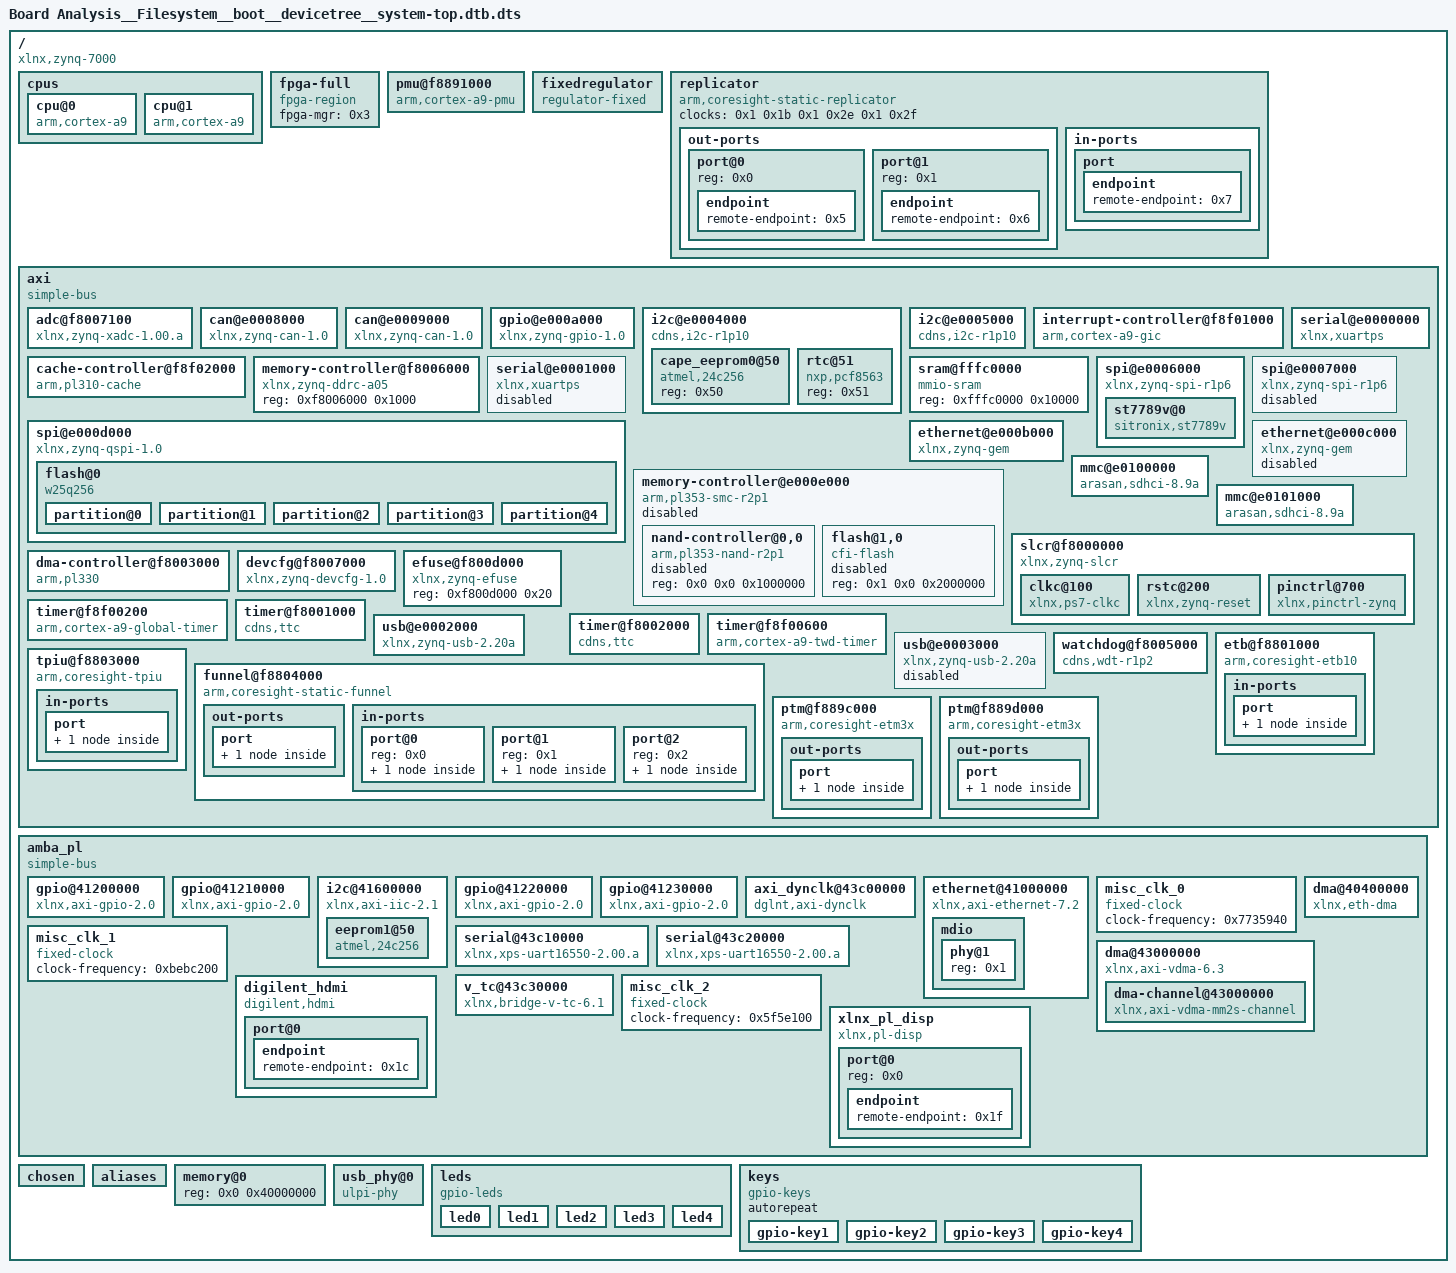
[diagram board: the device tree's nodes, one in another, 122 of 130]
/dts-v1/;
/ {
	#address-cells = <0x1>;
	#size-cells = <0x1>;
	compatible = "xlnx,zynq-7000";
	cpus {
		#address-cells = <0x1>;
		#size-cells = <0x0>;
		cpu@0 {
			compatible = "arm,cortex-a9";
			device_type = "cpu";
			reg = <0x0>;
			clocks = <0x1 0x3>;
			clock-latency = <0x3e8>;
			cpu0-supply = <0x2>;
			operating-points = <0xbb2ca 0xf4240 0x5d965 0xf4240>;
			phandle = <0x10>;
		};
		cpu@1 {
			compatible = "arm,cortex-a9";
			device_type = "cpu";
			reg = <0x1>;
			clocks = <0x1 0x3>;
			phandle = <0x12>;
		};
	};
	fpga-full {
		compatible = "fpga-region";
		fpga-mgr = <0x3>;
		#address-cells = <0x1>;
		#size-cells = <0x1>;
		ranges;
		phandle = <0x20>;
	};
	pmu@f8891000 {
		compatible = "arm,cortex-a9-pmu";
		interrupts = <0x0 0x5 0x4 0x0 0x6 0x4>;
		interrupt-parent = <0x4>;
		reg = <0xf8891000 0x1000 0xf8893000 0x1000>;
	};
	fixedregulator {
		compatible = "regulator-fixed";
		regulator-name = "VCCPINT";
		regulator-min-microvolt = <0xf4240>;
		regulator-max-microvolt = <0xf4240>;
		regulator-boot-on;
		regulator-always-on;
		phandle = <0x2>;
	};
	replicator {
		compatible = "arm,coresight-static-replicator";
		clocks = <0x1 0x1b 0x1 0x2e 0x1 0x2f>;
		clock-names = "apb_pclk", "dbg_trc", "dbg_apb";
		out-ports {
			#address-cells = <0x1>;
			#size-cells = <0x0>;
			port@0 {
				reg = <0x0>;
				endpoint {
					remote-endpoint = <0x5>;
					phandle = <0xc>;
				};
			};
			port@1 {
				reg = <0x1>;
				endpoint {
					remote-endpoint = <0x6>;
					phandle = <0xb>;
				};
			};
		};
		in-ports {
			port {
				endpoint {
					remote-endpoint = <0x7>;
					phandle = <0xd>;
				};
			};
		};
	};
	axi {
		u-boot,dm-pre-reloc;
		compatible = "simple-bus";
		#address-cells = <0x1>;
		#size-cells = <0x1>;
		interrupt-parent = <0x4>;
		ranges;
		phandle = <0x21>;
		adc@f8007100 {
			compatible = "xlnx,zynq-xadc-1.00.a";
			reg = <0xf8007100 0x20>;
			interrupts = <0x0 0x7 0x4>;
			interrupt-parent = <0x4>;
			clocks = <0x1 0xc>;
			phandle = <0x22>;
		};
		can@e0008000 {
			compatible = "xlnx,zynq-can-1.0";
			status = "okay";
			clocks = <0x1 0x13 0x1 0x24>;
			clock-names = "can_clk", "pclk";
			reg = <0xe0008000 0x1000>;
			interrupts = <0x0 0x1c 0x4>;
			interrupt-parent = <0x4>;
			tx-fifo-depth = <0x40>;
			rx-fifo-depth = <0x40>;
			phandle = <0x23>;
		};
		can@e0009000 {
			compatible = "xlnx,zynq-can-1.0";
			status = "okay";
			clocks = <0x1 0x14 0x1 0x25>;
			clock-names = "can_clk", "pclk";
			reg = <0xe0009000 0x1000>;
			interrupts = <0x0 0x33 0x4>;
			interrupt-parent = <0x4>;
			tx-fifo-depth = <0x40>;
			rx-fifo-depth = <0x40>;
			phandle = <0x24>;
		};
		gpio@e000a000 {
			compatible = "xlnx,zynq-gpio-1.0";
			#gpio-cells = <0x2>;
			clocks = <0x1 0x2a>;
			gpio-controller;
			interrupt-controller;
			#interrupt-cells = <0x2>;
			interrupt-parent = <0x4>;
			interrupts = <0x0 0x14 0x4>;
			reg = <0xe000a000 0x1000>;
			emio-gpio-width = <0xb>;
			gpio-mask-high = <0x0>;
			gpio-mask-low = <0x5600>;
			phandle = <0x8>;
		};
		i2c@e0004000 {
			compatible = "cdns,i2c-r1p10";
			status = "okay";
			clocks = <0x1 0x26>;
			interrupt-parent = <0x4>;
			interrupts = <0x0 0x19 0x4>;
			reg = <0xe0004000 0x1000>;
			#address-cells = <0x1>;
			#size-cells = <0x0>;
			clock-frequency = <0x186a0>;
			phandle = <0x25>;
			cape_eeprom0@50 {
				compatible = "atmel,24c256";
				reg = <0x50>;
				phandle = <0x26>;
			};
			rtc@51 {
				compatible = "nxp,pcf8563";
				reg = <0x51>;
			};
		};
		i2c@e0005000 {
			compatible = "cdns,i2c-r1p10";
			status = "okay";
			clocks = <0x1 0x27>;
			interrupt-parent = <0x4>;
			interrupts = <0x0 0x30 0x4>;
			reg = <0xe0005000 0x1000>;
			#address-cells = <0x1>;
			#size-cells = <0x0>;
			clock-frequency = <0x186a0>;
			phandle = <0x1b>;
		};
		interrupt-controller@f8f01000 {
			compatible = "arm,cortex-a9-gic";
			#interrupt-cells = <0x3>;
			interrupt-controller;
			reg = <0xf8f01000 0x1000 0xf8f00100 0x100>;
			num_cpus = <0x2>;
			num_interrupts = <0x60>;
			phandle = <0x4>;
		};
		cache-controller@f8f02000 {
			compatible = "arm,pl310-cache";
			reg = <0xf8f02000 0x1000>;
			interrupts = <0x0 0x2 0x4>;
			arm,data-latency = <0x3 0x2 0x2>;
			arm,tag-latency = <0x2 0x2 0x2>;
			cache-unified;
			cache-level = <0x2>;
			phandle = <0x27>;
		};
		memory-controller@f8006000 {
			compatible = "xlnx,zynq-ddrc-a05";
			reg = <0xf8006000 0x1000>;
			phandle = <0x28>;
		};
		sram@fffc0000 {
			compatible = "mmio-sram";
			reg = <0xfffc0000 0x10000>;
			phandle = <0x29>;
		};
		serial@e0000000 {
			compatible = "xlnx,xuartps", "cdns,uart-r1p8";
			status = "okay";
			clocks = <0x1 0x17 0x1 0x28>;
			clock-names = "uart_clk", "pclk";
			reg = <0xe0000000 0x1000>;
			interrupts = <0x0 0x1b 0x4>;
			cts-override;
			device_type = "serial";
			port-number = <0x0>;
			phandle = <0x2a>;
		};
		serial@e0001000 {
			compatible = "xlnx,xuartps", "cdns,uart-r1p8";
			status = "disabled";
			clocks = <0x1 0x18 0x1 0x29>;
			clock-names = "uart_clk", "pclk";
			reg = <0xe0001000 0x1000>;
			interrupts = <0x0 0x32 0x4>;
			phandle = <0x2b>;
		};
		spi@e0006000 {
			compatible = "xlnx,zynq-spi-r1p6";
			reg = <0xe0006000 0x1000>;
			status = "okay";
			interrupt-parent = <0x4>;
			interrupts = <0x0 0x1a 0x4>;
			clocks = <0x1 0x19 0x1 0x22>;
			clock-names = "ref_clk", "pclk";
			#address-cells = <0x1>;
			#size-cells = <0x0>;
			is-decoded-cs = <0x0>;
			num-cs = <0x3>;
			phandle = <0x2c>;
			st7789v@0 {
				status = "okay";
				compatible = "sitronix,st7789v";
				reg = <0x0>;
				spi-max-frequency = <0x1e84800>;
				rotate = <0x10e>;
				spi-cpol;
				spi-cpha;
				rgb;
				fps = <0x1e>;
				buswidth = <0x8>;
				reset-gpios = <0x8 0x3d 0x1>;
				dc-gpios = <0x8 0x3b 0x0>;
				width = <0xac>;
				height = <0x140>;
				debug = <0x0>;
			};
		};
		spi@e0007000 {
			compatible = "xlnx,zynq-spi-r1p6";
			reg = <0xe0007000 0x1000>;
			status = "disabled";
			interrupt-parent = <0x4>;
			interrupts = <0x0 0x31 0x4>;
			clocks = <0x1 0x1a 0x1 0x23>;
			clock-names = "ref_clk", "pclk";
			#address-cells = <0x1>;
			#size-cells = <0x0>;
			phandle = <0x2d>;
		};
		spi@e000d000 {
			compatible = "xlnx,zynq-qspi-1.0";
			reg = <0xe000d000 0x1000>;
			interrupt-parent = <0x4>;
			interrupts = <0x0 0x13 0x4>;
			clocks = <0x1 0xa 0x1 0x2b>;
			clock-names = "ref_clk", "pclk";
			status = "okay";
			#address-cells = <0x1>;
			#size-cells = <0x0>;
			is-dual = <0x0>;
			num-cs = <0x1>;
			spi-rx-bus-width = <0x4>;
			spi-tx-bus-width = <0x4>;
			phandle = <0x2e>;
			flash@0 {
				compatible = "w25q256", "jedec,spi-nor";
				reg = <0x0>;
				spi-max-frequency = <0x2faf080>;
				#address-cells = <0x1>;
				#size-cells = <0x1>;
				phandle = <0x2f>;
				partition@0 {
					label = "boot";
					reg = <0x0 0x800000>;
				};
				partition@1 {
					label = "bootenv";
					reg = <0x800000 0x20000>;
				};
				partition@2 {
					label = "kernel";
					reg = <0x820000 0xa80000>;
				};
				partition@3 {
					label = "boot.scr";
					reg = <0x12a0000 0x40000>;
				};
				partition@4 {
					label = "space";
					reg = <0x12e0000 0x0>;
				};
			};
		};
		ethernet@e000b000 {
			compatible = "xlnx,zynq-gem", "cdns,gem";
			reg = <0xe000b000 0x1000>;
			status = "okay";
			interrupts = <0x0 0x16 0x4>;
			clocks = <0x1 0x1e 0x1 0x1e 0x1 0xd>;
			clock-names = "pclk", "hclk", "tx_clk";
			#address-cells = <0x1>;
			#size-cells = <0x0>;
			phy-mode = "rgmii-id";
			xlnx,ptp-enet-clock = <0x79dbbf3>;
			local-mac-address = [00 0a 35 00 1e 53];
			phandle = <0x30>;
		};
		ethernet@e000c000 {
			compatible = "xlnx,zynq-gem", "cdns,gem";
			reg = <0xe000c000 0x1000>;
			status = "disabled";
			interrupts = <0x0 0x2d 0x4>;
			clocks = <0x1 0x1f 0x1 0x1f 0x1 0xe>;
			clock-names = "pclk", "hclk", "tx_clk";
			#address-cells = <0x1>;
			#size-cells = <0x0>;
			phandle = <0x31>;
		};
		memory-controller@e000e000 {
			compatible = "arm,pl353-smc-r2p1", "arm,primecell";
			reg = <0xe000e000 0x1000>;
			status = "disabled";
			clock-names = "memclk", "apb_pclk";
			clocks = <0x1 0xb 0x1 0x2c>;
			ranges = <0x0 0x0 0xe1000000 0x1000000 0x1 0x0 0xe2000000 0x2000000 0x2 0x0 0xe4000000 0x2000000>;
			#address-cells = <0x2>;
			#size-cells = <0x1>;
			interrupt-parent = <0x4>;
			interrupts = <0x0 0x12 0x4>;
			phandle = <0x32>;
			nand-controller@0,0 {
				compatible = "arm,pl353-nand-r2p1";
				reg = <0x0 0x0 0x1000000>;
				status = "disabled";
				#address-cells = <0x1>;
				#size-cells = <0x0>;
				phandle = <0x33>;
			};
			flash@1,0 {
				status = "disabled";
				compatible = "cfi-flash";
				reg = <0x1 0x0 0x2000000>;
				#address-cells = <0x1>;
				#size-cells = <0x1>;
				phandle = <0x34>;
			};
		};
		mmc@e0100000 {
			compatible = "arasan,sdhci-8.9a";
			status = "okay";
			clock-names = "clk_xin", "clk_ahb";
			clocks = <0x1 0x15 0x1 0x20>;
			interrupt-parent = <0x4>;
			interrupts = <0x0 0x18 0x4>;
			reg = <0xe0100000 0x1000>;
			xlnx,has-cd = <0x1>;
			xlnx,has-power = <0x0>;
			xlnx,has-wp = <0x0>;
			u-boot,dm-pre-reloc;
			phandle = <0x35>;
		};
		mmc@e0101000 {
			compatible = "arasan,sdhci-8.9a";
			status = "okay";
			clock-names = "clk_xin", "clk_ahb";
			clocks = <0x1 0x16 0x1 0x21>;
			interrupt-parent = <0x4>;
			interrupts = <0x0 0x2f 0x4>;
			reg = <0xe0101000 0x1000>;
			xlnx,has-cd = <0x0>;
			xlnx,has-power = <0x0>;
			xlnx,has-wp = <0x0>;
			phandle = <0x36>;
		};
		slcr@f8000000 {
			u-boot,dm-pre-reloc;
			#address-cells = <0x1>;
			#size-cells = <0x1>;
			compatible = "xlnx,zynq-slcr", "syscon", "simple-mfd";
			reg = <0xf8000000 0x1000>;
			ranges;
			phandle = <0x9>;
			clkc@100 {
				u-boot,dm-pre-reloc;
				#clock-cells = <0x1>;
				compatible = "xlnx,ps7-clkc";
				fclk-enable = <0x3>;
				clock-output-names = "armpll", "ddrpll", "iopll", "cpu_6or4x", "cpu_3or2x", "cpu_2x", "cpu_1x", "ddr2x", "ddr3x", "dci", "lqspi", "smc", "pcap", "gem0", "gem1", "fclk0", "fclk1", "fclk2", "fclk3", "can0", "can1", "sdio0", "sdio1", "uart0", "uart1", "spi0", "spi1", "dma", "usb0_aper", "usb1_aper", "gem0_aper", "gem1_aper", "sdio0_aper", "sdio1_aper", "spi0_aper", "spi1_aper", "can0_aper", "can1_aper", "i2c0_aper", "i2c1_aper", "uart0_aper", "uart1_aper", "gpio_aper", "lqspi_aper", "smc_aper", "swdt", "dbg_trc", "dbg_apb";
				reg = <0x100 0x100>;
				ps-clk-frequency = <0x1fca055>;
				phandle = <0x1>;
			};
			rstc@200 {
				compatible = "xlnx,zynq-reset";
				reg = <0x200 0x48>;
				#reset-cells = <0x1>;
				syscon = <0x9>;
				phandle = <0x37>;
			};
			pinctrl@700 {
				compatible = "xlnx,pinctrl-zynq";
				reg = <0x700 0x200>;
				syscon = <0x9>;
				phandle = <0x38>;
			};
		};
		dma-controller@f8003000 {
			compatible = "arm,pl330", "arm,primecell";
			reg = <0xf8003000 0x1000>;
			interrupt-parent = <0x4>;
			interrupts = <0x0 0xd 0x4 0x0 0xe 0x4 0x0 0xf 0x4 0x0 0x10 0x4 0x0 0x11 0x4 0x0 0x28 0x4 0x0 0x29 0x4 0x0 0x2a 0x4 0x0 0x2b 0x4>;
			#dma-cells = <0x1>;
			clocks = <0x1 0x1b>;
			clock-names = "apb_pclk";
			phandle = <0x39>;
		};
		devcfg@f8007000 {
			compatible = "xlnx,zynq-devcfg-1.0";
			reg = <0xf8007000 0x100>;
			interrupt-parent = <0x4>;
			interrupts = <0x0 0x8 0x4>;
			clocks = <0x1 0xc 0x1 0xf 0x1 0x10 0x1 0x11 0x1 0x12>;
			clock-names = "ref_clk", "fclk0", "fclk1", "fclk2", "fclk3";
			syscon = <0x9>;
			phandle = <0x3>;
		};
		efuse@f800d000 {
			compatible = "xlnx,zynq-efuse";
			reg = <0xf800d000 0x20>;
			phandle = <0x3a>;
		};
		timer@f8f00200 {
			compatible = "arm,cortex-a9-global-timer";
			reg = <0xf8f00200 0x20>;
			interrupts = <0x1 0xb 0x301>;
			interrupt-parent = <0x4>;
			clocks = <0x1 0x4>;
			phandle = <0x3b>;
		};
		timer@f8001000 {
			interrupt-parent = <0x4>;
			interrupts = <0x0 0xa 0x4 0x0 0xb 0x4 0x0 0xc 0x4>;
			compatible = "cdns,ttc";
			clocks = <0x1 0x6>;
			reg = <0xf8001000 0x1000>;
			phandle = <0x3c>;
		};
		timer@f8002000 {
			interrupt-parent = <0x4>;
			interrupts = <0x0 0x25 0x4 0x0 0x26 0x4 0x0 0x27 0x4>;
			compatible = "cdns,ttc";
			clocks = <0x1 0x6>;
			reg = <0xf8002000 0x1000>;
			phandle = <0x3d>;
		};
		timer@f8f00600 {
			interrupt-parent = <0x4>;
			interrupts = <0x1 0xd 0x301>;
			compatible = "arm,cortex-a9-twd-timer";
			reg = <0xf8f00600 0x20>;
			clocks = <0x1 0x4>;
			phandle = <0x3e>;
		};
		usb@e0002000 {
			compatible = "xlnx,zynq-usb-2.20a", "chipidea,usb2";
			status = "okay";
			clocks = <0x1 0x1c>;
			interrupt-parent = <0x4>;
			interrupts = <0x0 0x15 0x4>;
			reg = <0xe0002000 0x1000>;
			phy_type = "ulpi";
			usb-reset = <0x8 0xd 0x0>;
			dr_mode = "host";
			usb-phy = <0xa>;
			phandle = <0x3f>;
		};
		usb@e0003000 {
			compatible = "xlnx,zynq-usb-2.20a", "chipidea,usb2";
			status = "disabled";
			clocks = <0x1 0x1d>;
			interrupt-parent = <0x4>;
			interrupts = <0x0 0x2c 0x4>;
			reg = <0xe0003000 0x1000>;
			phy_type = "ulpi";
			phandle = <0x40>;
		};
		watchdog@f8005000 {
			clocks = <0x1 0x2d>;
			compatible = "cdns,wdt-r1p2";
			interrupt-parent = <0x4>;
			interrupts = <0x0 0x9 0x1>;
			reg = <0xf8005000 0x1000>;
			timeout-sec = <0xa>;
			phandle = <0x41>;
		};
		etb@f8801000 {
			compatible = "arm,coresight-etb10", "arm,primecell";
			reg = <0xf8801000 0x1000>;
			clocks = <0x1 0x1b 0x1 0x2e 0x1 0x2f>;
			clock-names = "apb_pclk", "dbg_trc", "dbg_apb";
			in-ports {
				port {
					endpoint {
						remote-endpoint = <0xb>;
						phandle = <0x6>;
					};
				};
			};
		};
		tpiu@f8803000 {
			compatible = "arm,coresight-tpiu", "arm,primecell";
			reg = <0xf8803000 0x1000>;
			clocks = <0x1 0x1b 0x1 0x2e 0x1 0x2f>;
			clock-names = "apb_pclk", "dbg_trc", "dbg_apb";
			in-ports {
				port {
					endpoint {
						remote-endpoint = <0xc>;
						phandle = <0x5>;
					};
				};
			};
		};
		funnel@f8804000 {
			compatible = "arm,coresight-static-funnel", "arm,primecell";
			reg = <0xf8804000 0x1000>;
			clocks = <0x1 0x1b 0x1 0x2e 0x1 0x2f>;
			clock-names = "apb_pclk", "dbg_trc", "dbg_apb";
			out-ports {
				port {
					endpoint {
						remote-endpoint = <0xd>;
						phandle = <0x7>;
					};
				};
			};
			in-ports {
				#address-cells = <0x1>;
				#size-cells = <0x0>;
				port@0 {
					reg = <0x0>;
					endpoint {
						remote-endpoint = <0xe>;
						phandle = <0x11>;
					};
				};
				port@1 {
					reg = <0x1>;
					endpoint {
						remote-endpoint = <0xf>;
						phandle = <0x13>;
					};
				};
				port@2 {
					reg = <0x2>;
					endpoint {
						phandle = <0x42>;
					};
				};
			};
		};
		ptm@f889c000 {
			compatible = "arm,coresight-etm3x", "arm,primecell";
			reg = <0xf889c000 0x1000>;
			clocks = <0x1 0x1b 0x1 0x2e 0x1 0x2f>;
			clock-names = "apb_pclk", "dbg_trc", "dbg_apb";
			cpu = <0x10>;
			out-ports {
				port {
					endpoint {
						remote-endpoint = <0x11>;
						phandle = <0xe>;
					};
				};
			};
		};
		ptm@f889d000 {
			compatible = "arm,coresight-etm3x", "arm,primecell";
			reg = <0xf889d000 0x1000>;
			clocks = <0x1 0x1b 0x1 0x2e 0x1 0x2f>;
			clock-names = "apb_pclk", "dbg_trc", "dbg_apb";
			cpu = <0x12>;
			out-ports {
				port {
					endpoint {
						remote-endpoint = <0x13>;
						phandle = <0xf>;
					};
				};
			};
		};
	};
	amba_pl {
		#address-cells = <0x1>;
		#size-cells = <0x1>;
		compatible = "simple-bus";
		ranges;
		phandle = <0x43>;
		gpio@41200000 {
			#gpio-cells = <0x2>;
			clock-names = "s_axi_aclk";
			clocks = <0x1 0xf>;
			compatible = "xlnx,axi-gpio-2.0", "xlnx,xps-gpio-1.00.a";
			gpio-controller;
			reg = <0x41200000 0x10000>;
			xlnx,all-inputs = <0x0>;
			xlnx,all-inputs-2 = <0x0>;
			xlnx,all-outputs = <0x0>;
			xlnx,all-outputs-2 = <0x0>;
			xlnx,dout-default = <0x0>;
			xlnx,dout-default-2 = <0x0>;
			xlnx,gpio-width = <0x20>;
			xlnx,gpio2-width = <0x20>;
			xlnx,interrupt-present = <0x0>;
			xlnx,is-dual = <0x1>;
			xlnx,tri-default = <0xffffffff>;
			xlnx,tri-default-2 = <0xffffffff>;
			phandle = <0x44>;
		};
		gpio@41210000 {
			#gpio-cells = <0x2>;
			clock-names = "s_axi_aclk";
			clocks = <0x1 0xf>;
			compatible = "xlnx,axi-gpio-2.0", "xlnx,xps-gpio-1.00.a";
			gpio-controller;
			reg = <0x41210000 0x10000>;
			xlnx,all-inputs = <0x0>;
			xlnx,all-inputs-2 = <0x0>;
			xlnx,all-outputs = <0x0>;
			xlnx,all-outputs-2 = <0x0>;
			xlnx,dout-default = <0x0>;
			xlnx,dout-default-2 = <0x0>;
			xlnx,gpio-width = <0x8>;
			xlnx,gpio2-width = <0x20>;
			xlnx,interrupt-present = <0x0>;
			xlnx,is-dual = <0x0>;
			xlnx,tri-default = <0xffffffff>;
			xlnx,tri-default-2 = <0xffffffff>;
			phandle = <0x45>;
		};
		i2c@41600000 {
			#address-cells = <0x1>;
			#size-cells = <0x0>;
			clock-names = "s_axi_aclk";
			clocks = <0x1 0xf>;
			compatible = "xlnx,axi-iic-2.1", "xlnx,xps-iic-2.00.a";
			interrupt-names = "iic2intc_irpt";
			interrupt-parent = <0x4>;
			interrupts = <0x0 0x34 0x4>;
			reg = <0x41600000 0x10000>;
			clock-frequency = <0x186a0>;
			phandle = <0x46>;
			eeprom1@50 {
				compatible = "atmel,24c256";
				reg = <0x50>;
				pagesize = <0x20>;
			};
		};
		gpio@41220000 {
			#gpio-cells = <0x2>;
			clock-names = "s_axi_aclk";
			clocks = <0x1 0xf>;
			compatible = "xlnx,axi-gpio-2.0", "xlnx,xps-gpio-1.00.a";
			gpio-controller;
			reg = <0x41220000 0x10000>;
			xlnx,all-inputs = <0x0>;
			xlnx,all-inputs-2 = <0x0>;
			xlnx,all-outputs = <0x0>;
			xlnx,all-outputs-2 = <0x0>;
			xlnx,dout-default = <0x0>;
			xlnx,dout-default-2 = <0x0>;
			xlnx,gpio-width = <0x20>;
			xlnx,gpio2-width = <0x2>;
			xlnx,interrupt-present = <0x0>;
			xlnx,is-dual = <0x1>;
			xlnx,tri-default = <0xffffffff>;
			xlnx,tri-default-2 = <0xffffffff>;
			phandle = <0x47>;
		};
		gpio@41230000 {
			#gpio-cells = <0x2>;
			clock-names = "s_axi_aclk";
			clocks = <0x1 0xf>;
			compatible = "xlnx,axi-gpio-2.0", "xlnx,xps-gpio-1.00.a";
			gpio-controller;
			reg = <0x41230000 0x10000>;
			xlnx,all-inputs = <0x0>;
			xlnx,all-inputs-2 = <0x0>;
			xlnx,all-outputs = <0x0>;
			xlnx,all-outputs-2 = <0x0>;
			xlnx,dout-default = <0x0>;
			xlnx,dout-default-2 = <0x0>;
			xlnx,gpio-width = <0x2>;
			xlnx,gpio2-width = <0x20>;
			xlnx,interrupt-present = <0x0>;
			xlnx,is-dual = <0x0>;
			xlnx,tri-default = <0xffffffff>;
			xlnx,tri-default-2 = <0xffffffff>;
			phandle = <0x48>;
		};
		axi_dynclk@43c00000 {
			clock-names = "REF_CLK_I", "s_axi_lite_aclk";
			clocks = <0x1 0xf>;
			compatible = "dglnt,axi-dynclk";
			reg = <0x43c00000 0x10000>;
			#clock-cells = <0x0>;
			phandle = <0x1a>;
		};
		ethernet@41000000 {
			axistream-connected = <0x14>;
			axistream-control-connected = <0x14>;
			clock-frequency = <0x5f5e100>;
			clock-names = "s_axi_lite_clk", "axis_clk", "gtx_clk", "ref_clk";
			clocks = <0x1 0xf 0x1 0xf 0x15 0x16>;
			compatible = "xlnx,axi-ethernet-7.2", "xlnx,axi-ethernet-1.00.a";
			device_type = "network";
			interrupt-names = "mac_irq", "interrupt", "mm2s_introut", "s2mm_introut";
			interrupt-parent = <0x4>;
			interrupts = <0x0 0x1d 0x1 0x0 0x1e 0x4 0x0 0x1f 0x4 0x0 0x20 0x4>;
			local-mac-address = [00 0a 35 00 01 22];
			phy-mode = "rgmii-rxid";
			reg = <0x41000000 0x40000>;
			xlnx = <0x0>;
			xlnx,axiliteclkrate = <0x0>;
			xlnx,axisclkrate = <0x0>;
			xlnx,channel-ids = "1";
			xlnx,clockselection = <0x0>;
			xlnx,enableasyncsgmii = <0x0>;
			xlnx,gt-type = <0x0>;
			xlnx,gtinex = <0x0>;
			xlnx,gtlocation = <0x0>;
			xlnx,gtrefclksrc = <0x0>;
			xlnx,include-dre;
			xlnx,instantiatebitslice0 = <0x0>;
			xlnx,num-queues = [00 01];
			xlnx,phyaddr = <0x1>;
			xlnx,phyrst-board-interface-dummy-port = <0x0>;
			xlnx,rable = <0x0>;
			xlnx,rxcsum = <0x2>;
			xlnx,rxlane0-placement = <0x0>;
			xlnx,rxlane1-placement = <0x0>;
			xlnx,rxmem = <0x4000>;
			xlnx,rxnibblebitslice0used = <0x0>;
			xlnx,tx-in-upper-nibble = <0x1>;
			xlnx,txcsum = <0x2>;
			xlnx,txlane0-placement = <0x0>;
			xlnx,txlane1-placement = <0x0>;
			xlnx,versal-gt-board-flow = <0x0>;
			zclock-names = "NULL";
			zclocks = "NULL";
			phy-handle = <0x17>;
			xlnx,has-mdio = <0x1>;
			phandle = <0x18>;
			mdio {
				#address-cells = <0x1>;
				#size-cells = <0x0>;
				phandle = <0x49>;
				phy@1 {
					device_type = "ethernet-phy";
					reg = <0x1>;
					phandle = <0x17>;
				};
			};
		};
		misc_clk_0 {
			#clock-cells = <0x0>;
			clock-frequency = <0x7735940>;
			compatible = "fixed-clock";
			phandle = <0x15>;
		};
		misc_clk_1 {
			#clock-cells = <0x0>;
			clock-frequency = <0xbebc200>;
			compatible = "fixed-clock";
			phandle = <0x16>;
		};
		dma@40400000 {
			#dma-cells = <0x1>;
			axistream-connected = <0x18>;
			axistream-control-connected = <0x18>;
			clock-names = "s_axi_lite_aclk", "m_axi_sg_aclk", "m_axi_mm2s_aclk", "m_axi_s2mm_aclk";
			clocks = <0x1 0xf 0x1 0xf 0x1 0xf 0x1 0xf>;
			compatible = "xlnx,eth-dma";
			interrupt-names = "mm2s_introut", "s2mm_introut";
			interrupt-parent = <0x4>;
			interrupts = <0x0 0x1f 0x4 0x0 0x20 0x4>;
			reg = <0x40400000 0x10000>;
			xlnx,addrwidth = [20];
			xlnx,include-dre;
			xlnx,num-queues = [00 01];
			phandle = <0x14>;
		};
		serial@43c10000 {
			clock-frequency = <0x5f5e100>;
			clock-names = "s_axi_aclk";
			clocks = <0x1 0xf>;
			compatible = "xlnx,xps-uart16550-2.00.a", "ns16550a";
			current-speed = <0x1c200>;
			device_type = "serial";
			interrupt-names = "ip2intc_irpt";
			interrupt-parent = <0x4>;
			interrupts = <0x0 0x22 0x4>;
			port-number = <0x1>;
			reg = <0x43c10000 0x10000>;
			reg-offset = <0x1000>;
			reg-shift = <0x2>;
			xlnx,external-xin-clk-hz = <0x17d7840>;
			xlnx,external-xin-clk-hz-d = <0x19>;
			xlnx,has-external-rclk = <0x0>;
			xlnx,has-external-xin = <0x0>;
			xlnx,is-a-16550 = <0x1>;
			xlnx,s-axi-aclk-freq-hz-d = "100.0";
			xlnx,sim-device = "VERSAL_AI_CORE_ES1";
			xlnx,use-modem-ports = <0x1>;
			xlnx,use-user-ports = <0x1>;
			phandle = <0x4a>;
		};
		serial@43c20000 {
			clock-frequency = <0x5f5e100>;
			clock-names = "s_axi_aclk";
			clocks = <0x1 0xf>;
			compatible = "xlnx,xps-uart16550-2.00.a", "ns16550a";
			current-speed = <0x1c200>;
			device_type = "serial";
			interrupt-names = "ip2intc_irpt";
			interrupt-parent = <0x4>;
			interrupts = <0x0 0x23 0x4>;
			port-number = <0x2>;
			reg = <0x43c20000 0x10000>;
			reg-offset = <0x1000>;
			reg-shift = <0x2>;
			xlnx,external-xin-clk-hz = <0x17d7840>;
			xlnx,external-xin-clk-hz-d = <0x19>;
			xlnx,has-external-rclk = <0x0>;
			xlnx,has-external-xin = <0x0>;
			xlnx,is-a-16550 = <0x1>;
			xlnx,s-axi-aclk-freq-hz-d = "100.0";
			xlnx,sim-device = "VERSAL_AI_CORE_ES1";
			xlnx,use-modem-ports = <0x1>;
			xlnx,use-user-ports = <0x1>;
			phandle = <0x4b>;
		};
		dma@43000000 {
			#dma-cells = <0x1>;
			clock-names = "s_axi_lite_aclk", "m_axi_mm2s_aclk", "m_axis_mm2s_aclk";
			clocks = <0x1 0xf 0x1 0x10 0x1 0x10>;
			compatible = "xlnx,axi-vdma-6.3", "xlnx,axi-vdma-1.00.a";
			interrupt-names = "mm2s_introut";
			interrupt-parent = <0x4>;
			interrupts = <0x0 0x21 0x4>;
			reg = <0x43000000 0x10000>;
			xlnx,addrwidth = <0x20>;
			xlnx,flush-fsync = <0x1>;
			xlnx,num-fstores = <0x1>;
			phandle = <0x1d>;
			dma-channel@43000000 {
				compatible = "xlnx,axi-vdma-mm2s-channel";
				interrupts = <0x0 0x21 0x4>;
				xlnx,datawidth = <0x18>;
				xlnx,device-id = <0x0>;
				xlnx,genlock-mode;
				xlnx,include-dre;
			};
		};
		v_tc@43c30000 {
			clock-names = "clk", "s_axi_aclk";
			clocks = <0x19 0x1 0xf>;
			compatible = "xlnx,bridge-v-tc-6.1";
			interrupt-names = "irq";
			interrupt-parent = <0x4>;
			interrupts = <0x0 0x24 0x4>;
			reg = <0x43c30000 0x10000>;
			xlnx,generator;
			xlnx,pixels-per-clock = <0x1>;
			phandle = <0x1e>;
		};
		misc_clk_2 {
			#clock-cells = <0x0>;
			clock-frequency = <0x5f5e100>;
			compatible = "fixed-clock";
			phandle = <0x19>;
		};
		digilent_hdmi {
			compatible = "digilent,hdmi";
			clocks = <0x1a>;
			clock-names = "clk";
			digilent,edid-i2c = <0x1b>;
			digilent,fmax = <0x249f0>;
			port@0 {
				#address-cells = <0x1>;
				#size-cells = <0x0>;
				endpoint {
					remote-endpoint = <0x1c>;
					phandle = <0x1f>;
				};
			};
		};
		xlnx_pl_disp {
			compatible = "xlnx,pl-disp";
			dmas = <0x1d 0x0>;
			dma-names = "dma0";
			xlnx,vformat = "RG24";
			xlnx,bridge = <0x1e>;
			port@0 {
				reg = <0x0>;
				endpoint {
					remote-endpoint = <0x1f>;
					phandle = <0x1c>;
				};
			};
		};
	};
	chosen {
		bootargs = "console=ttyPS0,115200 earlycon root=/dev/mmcblk0p2 rw rootwait";
		stdout-path = "serial0:115200n8";
	};
	aliases {
		ethernet0 = "/axi/ethernet@e000b000";
		ethernet1 = "/amba_pl/ethernet@41000000";
		i2c0 = "/axi/i2c@e0004000";
		i2c1 = "/axi/i2c@e0005000";
		i2c2 = "/amba_pl/i2c@41600000";
		serial0 = "/axi/serial@e0000000";
		serial1 = "/amba_pl/serial@43c20000";
		serial2 = "/amba_pl/serial@43c10000";
		spi0 = "/axi/spi@e000d000";
		spi1 = "/axi/spi@e0006000";
	};
	memory@0 {
		device_type = "memory";
		reg = <0x0 0x40000000>;
	};
	usb_phy@0 {
		compatible = "ulpi-phy";
		#phy-cells = <0x0>;
		reg = <0xe0002000 0x1000>;
		view-port = <0x170>;
		drv-vbus;
		phandle = <0xa>;
	};
	leds {
		compatible = "gpio-leds";
		led0 {
			label = "ps_led1";
			gpios = <0x8 0x8 0x0>;
			default-state = "off";
		};
		led1 {
			label = "ps_led2";
			gpios = <0x8 0x7 0x0>;
			default-state = "off";
		};
		led2 {
			label = "pl_led1";
			gpios = <0x8 0x36 0x0>;
			default-state = "off";
		};
		led3 {
			label = "pl_led2";
			gpios = <0x8 0x37 0x0>;
			default-state = "off";
		};
		led4 {
			label = "pl_prsnt";
			gpios = <0x8 0x3a 0x0>;
			linux,default-trigger = "heartbeat";
		};
	};
	keys {
		compatible = "gpio-keys";
		autorepeat;
		gpio-key1 {
			label = "ps_key1";
			gpios = <0x8 0x0 0x1>;
			linux,code = <0x67>;
			debounce-interval = <0x14>;
		};
		gpio-key2 {
			label = "ps_key2";
			gpios = <0x8 0xc 0x1>;
			linux,code = <0x6c>;
			debounce-interval = <0x14>;
		};
		gpio-key3 {
			label = "pl_key1";
			gpios = <0x8 0x38 0x1>;
			linux,code = <0x69>;
			debounce-interval = <0x14>;
		};
		gpio-key4 {
			label = "pl_key2";
			gpios = <0x8 0x39 0x1>;
			linux,code = <0x6a>;
			debounce-interval = <0x14>;
		};
	};
	__symbols__ {
		cpu0 = "/cpus/cpu@0";
		cpu1 = "/cpus/cpu@1";
		fpga_full = "/fpga-full";
		regulator_vccpint = "/fixedregulator";
		replicator_out_port0 = "/replicator/out-ports/port@0/endpoint";
		replicator_out_port1 = "/replicator/out-ports/port@1/endpoint";
		replicator_in_port0 = "/replicator/in-ports/port/endpoint";
		amba = "/axi";
		adc = "/axi/adc@f8007100";
		can0 = "/axi/can@e0008000";
		can1 = "/axi/can@e0009000";
		gpio0 = "/axi/gpio@e000a000";
		i2c0 = "/axi/i2c@e0004000";
		cape_eeprom0 = "/axi/i2c@e0004000/cape_eeprom0@50";
		i2c1 = "/axi/i2c@e0005000";
		intc = "/axi/interrupt-controller@f8f01000";
		L2 = "/axi/cache-controller@f8f02000";
		mc = "/axi/memory-controller@f8006000";
		ocm = "/axi/sram@fffc0000";
		uart0 = "/axi/serial@e0000000";
		uart1 = "/axi/serial@e0001000";
		spi0 = "/axi/spi@e0006000";
		spi1 = "/axi/spi@e0007000";
		qspi = "/axi/spi@e000d000";
		flash0 = "/axi/spi@e000d000/flash@0";
		gem0 = "/axi/ethernet@e000b000";
		gem1 = "/axi/ethernet@e000c000";
		smcc = "/axi/memory-controller@e000e000";
		nfc0 = "/axi/memory-controller@e000e000/nand-controller@0,0";
		nor0 = "/axi/memory-controller@e000e000/flash@1,0";
		sdhci0 = "/axi/mmc@e0100000";
		sdhci1 = "/axi/mmc@e0101000";
		slcr = "/axi/slcr@f8000000";
		clkc = "/axi/slcr@f8000000/clkc@100";
		rstc = "/axi/slcr@f8000000/rstc@200";
		pinctrl0 = "/axi/slcr@f8000000/pinctrl@700";
		dmac_s = "/axi/dma-controller@f8003000";
		devcfg = "/axi/devcfg@f8007000";
		efuse = "/axi/efuse@f800d000";
		global_timer = "/axi/timer@f8f00200";
		ttc0 = "/axi/timer@f8001000";
		ttc1 = "/axi/timer@f8002000";
		scutimer = "/axi/timer@f8f00600";
		usb0 = "/axi/usb@e0002000";
		usb1 = "/axi/usb@e0003000";
		watchdog0 = "/axi/watchdog@f8005000";
		etb_in_port = "/axi/etb@f8801000/in-ports/port/endpoint";
		tpiu_in_port = "/axi/tpiu@f8803000/in-ports/port/endpoint";
		funnel_out_port = "/axi/funnel@f8804000/out-ports/port/endpoint";
		funnel0_in_port0 = "/axi/funnel@f8804000/in-ports/port@0/endpoint";
		funnel0_in_port1 = "/axi/funnel@f8804000/in-ports/port@1/endpoint";
		funnel0_in_port2 = "/axi/funnel@f8804000/in-ports/port@2/endpoint";
		ptm0_out_port = "/axi/ptm@f889c000/out-ports/port/endpoint";
		ptm1_out_port = "/axi/ptm@f889d000/out-ports/port/endpoint";
		amba_pl = "/amba_pl";
		FMC1 = "/amba_pl/gpio@41200000";
		FMC2 = "/amba_pl/gpio@41210000";
		FMC_IIC = "/amba_pl/i2c@41600000";
		IO_40PIN = "/amba_pl/gpio@41220000";
		RS485_DE = "/amba_pl/gpio@41230000";
		axi_dynclk_0 = "/amba_pl/axi_dynclk@43c00000";
		axi_ethernet_0 = "/amba_pl/ethernet@41000000";
		axi_ethernet_0_mdio = "/amba_pl/ethernet@41000000/mdio";
		phy1 = "/amba_pl/ethernet@41000000/mdio/phy@1";
		misc_clk_0 = "/amba_pl/misc_clk_0";
		misc_clk_1 = "/amba_pl/misc_clk_1";
		axi_ethernet_0_dma = "/amba_pl/dma@40400000";
		axi_uart16550_0 = "/amba_pl/serial@43c10000";
		axi_uart16550_1 = "/amba_pl/serial@43c20000";
		axi_vdma_0 = "/amba_pl/dma@43000000";
		v_tc_0 = "/amba_pl/v_tc@43c30000";
		misc_clk_2 = "/amba_pl/misc_clk_2";
		hdmi_ep = "/amba_pl/digilent_hdmi/port@0/endpoint";
		pl_disp_ep = "/amba_pl/xlnx_pl_disp/port@0/endpoint";
		usb_phy0 = "/usb_phy@0";
	};
};
